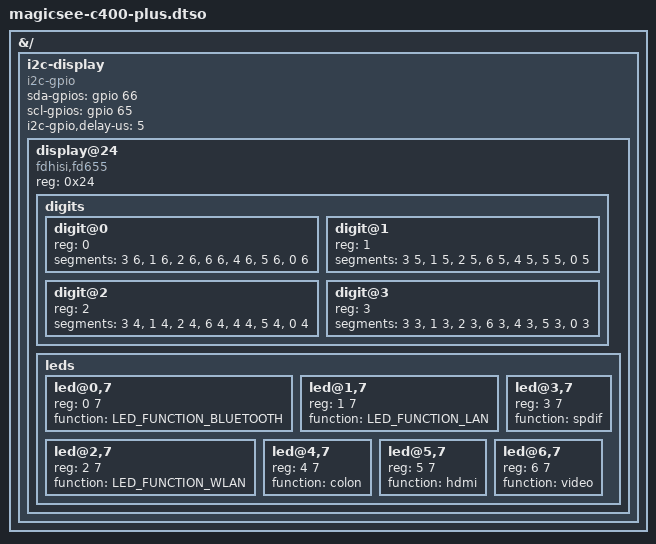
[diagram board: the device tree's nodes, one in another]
/dts-v1/;
/plugin/;

#include <dt-bindings/gpio/gpio.h>
#include <dt-bindings/leds/common.h>

&{/} {

	i2c-display {
		compatible = "i2c-gpio";
		sda-gpios = <&gpio 66 (GPIO_ACTIVE_HIGH | GPIO_OPEN_DRAIN)>;
		scl-gpios = <&gpio 65 (GPIO_ACTIVE_HIGH | GPIO_OPEN_DRAIN)>;
		i2c-gpio,delay-us = <5>;
		#address-cells = <1>;
		#size-cells = <0>;

		display@24 {
			compatible = "fdhisi,fd655";
			reg = <0x24>;

			digits {
				#address-cells = <1>;
				#size-cells = <0>;
				digit@0 {
					reg = <0>;
					segments = <3 6>,
						   <1 6>,
						   <2 6>,
						   <6 6>,
						   <4 6>,
						   <5 6>,
						   <0 6>;
				};
				digit@1 {
					reg = <1>;
					segments = <3 5>,
						   <1 5>,
						   <2 5>,
						   <6 5>,
						   <4 5>,
						   <5 5>,
						   <0 5>;
				};
				digit@2 {
					reg = <2>;
					segments = <3 4>,
						   <1 4>,
						   <2 4>,
						   <6 4>,
						   <4 4>,
						   <5 4>,
						   <0 4>;
				};
				digit@3 {
					reg = <3>;
					segments = <3 3>,
						   <1 3>,
						   <2 3>,
						   <6 3>,
						   <4 3>,
						   <5 3>,
						   <0 3>;
				};
			};

			leds {
				#address-cells = <2>;
				#size-cells = <0>;
				led@0,7 {
					reg = <0 7>;
					function = LED_FUNCTION_BLUETOOTH;
				};
				led@1,7 {
					reg = <1 7>;
					function = LED_FUNCTION_LAN;
				};
				led@2,7 {
					reg = <2 7>;
					function = LED_FUNCTION_WLAN;
				};
				led@3,7 {
					reg = <3 7>;
					function = "spdif";
				};
				led@4,7 {
					reg = <4 7>;
					function = "colon";
				};
				led@5,7 {
					reg = <5 7>;
					function = "hdmi";
				};
				led@6,7 {
					reg = <6 7>;
					function = "video";
				};
			};
		};
	};
};
